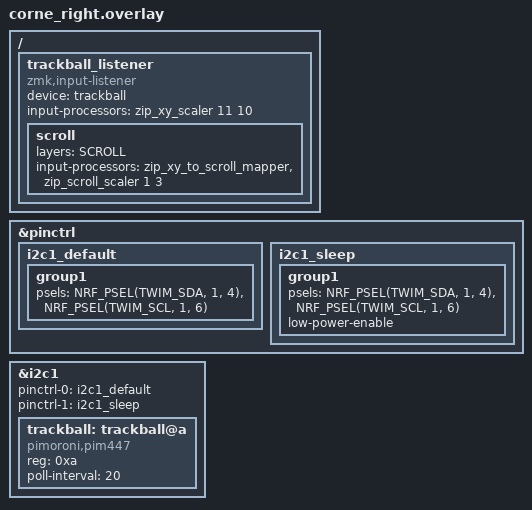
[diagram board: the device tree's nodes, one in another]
/*
 * Additions on top of the upstream corne_right shield.
 *
 * SPDX-License-Identifier: MIT
 */

#include "layers.h"
/* zip_* processor labels are /omit-if-no-ref/; nothing in ZMK includes this for us. */
#include <input/processors.dtsi>

&pinctrl {
	i2c1_default: i2c1_default {
		group1 {
			psels = <NRF_PSEL(TWIM_SDA, 1, 4)>,
				<NRF_PSEL(TWIM_SCL, 1, 6)>;
		};
	};

	i2c1_sleep: i2c1_sleep {
		group1 {
			psels = <NRF_PSEL(TWIM_SDA, 1, 4)>,
				<NRF_PSEL(TWIM_SCL, 1, 6)>;
			low-power-enable;
		};
	};
};

&i2c1 {
	status = "okay";
	pinctrl-0 = <&i2c1_default>;
	pinctrl-1 = <&i2c1_sleep>;
	pinctrl-names = "default", "sleep";

	trackball: trackball@a {
		compatible = "pimoroni,pim447";
		reg = <0xa>;
		/*
		 * poll-interval is the only property this driver reads. The ds87
		 * fork's tuning properties are not declared by our binding and were
		 * dead in the fork itself; feel lives in the input processors below.
		 */
		poll-interval = <20>;
	};
};

/ {
	trackball_listener {
		compatible = "zmk,input-listener";
		device = <&trackball>;
		input-processors = <&zip_xy_scaler 11 10>;

		scroll {
			layers = <SCROLL>;
			input-processors = <&zip_xy_to_scroll_mapper>, <&zip_scroll_scaler 1 3>;
		};
	};
};
